# SPC1068 register map
File version: 20180100_70611510
CPU: CM3 r2p1, little endian, MPU, no FPU, 4 interrupt priority bits
Registers are 32-bit, read-write, reset 0x0 unless marked. A register's access mark holds for its fields unless they carry their own. Offsets are from the block's base; [hi:lo] are bit positions; {n}, {i} and the like mark numbered series.

## TIMER0 — NOEN
Base 0x40001000
Same registers: TIMER1 0x40002000, TIMER2 0x4000C000
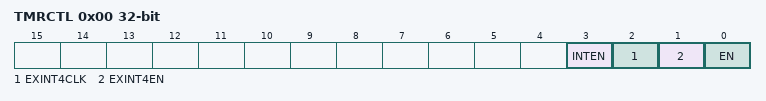
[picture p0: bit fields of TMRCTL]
0x00 TMRCTL — Timer Control Register
  [3] INTEN — Timer interrupt enable bit
    0=DISABLE (Disable timer interrupt); 1=ENABLE (Enable timer interrupt)
  [2] EXINT4CLK — Select external input as timer clock
    0=SEL_INTERNAL_CLK (Disable select external input as timer clock); 1=SEL_EXTERNAL_CLK (Enable Select external input as timer clock)
  [1] EXINT4EN — Select external input as timer enable
    0=NOT_SEL_EXTERNAL (Disable select external input as timer enable); 1=SEL_EXTERNAL (Enable select external input as timer enable)
  [0] EN — Timer Enable bit
    0=DISABLE (Disable Timer); 1=ENABLE (Enable Timer)
0x04 TMRCNT — Timer Counter Value Register
  [31:0] VAL — Current value of timer counter
0x08 TMRRELOAD — Timer Reload Value Register
  [31:0] VAL — Reload value, A Write to this registers sets the current value
0x0C TMRIF — Timer Interrupt Status Register
  [0] INT — Timer interrupt, Write one to clear
    0=NOT_OCCUR (Read a 0 indicates there is no timer interrupt. Write a 0 has no effect); 1=OCCUR (Read a 1 indicates a timer interrupt event. Write a 1 clear the timer interrupt)

## GPIO — General purpose input and output
Base 0x40003000
{0x0+4i} GPLR[{i}] (i=0..1) ro reset 0xE000001 — GPIO Pin Level Register 0
  [31:0] VAL — GPIOn pin level readback (n = 0~31). 0: GPIOn is low level. 1: GPIOn is high level
{0xC+4i} GPDR[{i}] (i=0..1) — GPIO Pin Direction Register 0
  [31:0] VAL — Set GPIOn direction (n = 0~31). 0: Set GPIOn as input. 1: Set GPIOn as output
{0x18+4i} GPSR[{i}] (i=0..1) wo — GPIO Pin Output Set Register 0
  [31:0] VAL — Set GPIOn output high (n = 0~31). 0: Unaffected. 1: Set GPIOn output to high
{0x24+4i} GPCR[{i}] (i=0..1) wo — GPIO Pin Output Clear Register 0
  [31:0] VAL — Set GPIOn output low (n = 0~31). 0: Unaffected. 1: Set GPIOn output to low
{0x30+4i} GRER[{i}] (i=0..1) — GPIO Rising Edge detect Enable Register 0
  [31:0] VAL — Enable GPIOn rising edge detect (n = 0~31). 0: Disable rising edge detection on GPIOn. 1: Enable rising edge detection on GPIOn
{0x3C+4i} GFER[{i}] (i=0..1) — GPIO Falling Edge detect Enable Register 0
  [31:0] VAL — Enable GPIOn falling edge detect (n = 0~31). 0: Disable falling edge detection on GPIOn. 1: Enable falling edge detection on GPIOn
{0x48+4i} GEDR[{i}] (i=0..1) — GPIO Edge detect Status Register 0
  [31:0] VAL — GPIOn edge detect status (n = 0~31). 0: Read 0 indicates no detected rising or falling edge. Write a 0 has no effect. 1: Read 1 indicates edge was detected. Write 1 will clear the latched status
{0x54+4i} GSDR[{i}] (i=0..1) wo — GPIO Pin Bitwise Set Direction Register 0
  [31:0] VAL — Set GPDR register bit (n = 0~31). 0: Unaffected. 1: Set GPDR bit and set GPIOn as output
{0x60+4i} GCDR[{i}] (i=0..1) wo — GPIO Pin Bitwise Clear Direction Register 0
  [31:0] VAL — Clear GPDR register bit (n = 0~31). 0: Unaffected. 1: Clear GPDR bit and set GPIOn as input
{0x6C+4i} GSRER[{i}] (i=0..1) wo — GPIO Bitwise Set Rising Edge detect Enable Register 0
  [31:0] VAL — Set GRER register bit (n = 0~31). 0: Unaffected. 1: Set GRER bit and enable rising edge detect for GPIOn
{0x78+4i} GCRER[{i}] (i=0..1) wo — GPIO Bitwise Clear Rising Edge detect Enable Register 0
  [31:0] VAL — Clear GRER register bit (n = 0~31). 0: Unaffected. 1: Clear GRER bit and disable rising edge detect for GPIOn
{0x84+4i} GSFER[{i}] (i=0..1) wo — GPIO Bitwise Set Falling Edge detect Enable Register 0
  [31:0] VAL — Set GFER register bit (n = 0~31). 0: Unaffected. 1: Set GFER bit and enable falling edge detect for GPIOn
{0x90+4i} GCFER[{i}] (i=0..1) wo — GPIO Bitwise Clear Falling Edge detect Enable Register 0
  [31:0] VAL — Clear GFER register bit (n = 0~31). 0: Unaffected. 1: Clear GFER bit and disable falling edge detect for GPIOn
{0x9C+4i} APMSK[{i}] (i=0..1) — GPIO Bitwise mask of Edge detect Status Register 0
  [31:0] VAL — Enable GPIOn edge detect (n = 0~31). 0: Disable GPIOn edge detect. 1: Enable GPIOn edge detect
